AUTOSAR XML (schema 00051)
package /MyTransmittingSWC
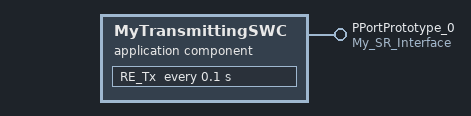
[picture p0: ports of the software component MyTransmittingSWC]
  application sw component type MyTransmittingSWC
    provide port PPortPrototype_0: provided-interface=My_SR_Interface
    behavior TxSwcInternalBehavior: data-type-mapping=MyDataTypeMappingSet, supports-multiple-instantiation=true
      timing event TE_TX: start-on-event=RE_Tx, period=0.1
      runnable RE_Tx: symbol=RE_Tx_func
        data-send-points:
          access DSP_DE_MyDataElement_0: accessed-variable=PPortPrototype_0.DE_MyDataElement
